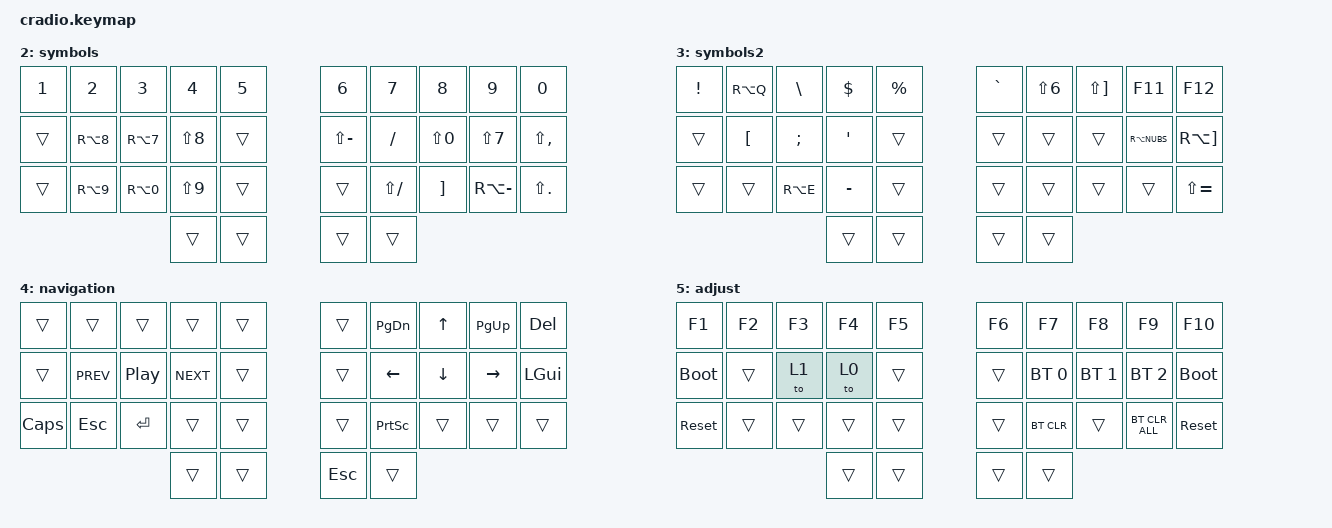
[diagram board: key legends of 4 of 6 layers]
#include <behaviors.dtsi>
#include <dt-bindings/zmk/keys.h>
#include <dt-bindings/zmk/bt.h>

// Home row mods macro
#define HRML(k1,k2,k3,k4) &hrm LGUI k1  &hrm LALT k2  &hrm LSHFT k3  &hrm LCTRL k4
#define HRMR(k1,k2,k3,k4) &hrm RCTRL k1  &hrm RSHFT k2  &hrm LALT k3  &hrm LGUI k4

&lt {
    flavor = "balanced";
    tapping-term-ms = <225>;
};

&sk {
    release-after-ms = <125>;
    quick-release;
};

/ {
    behaviors {
        hrm: home_row_mod {
            compatible = "zmk,behavior-hold-tap";
            #binding-cells = <2>;
            flavor = "balanced";
            tapping-term-ms = <225>;
            quick-tap-ms = <150>;
            require-prior-idle-ms = <150>;
            bindings = <&kp>, <&kp>;
        };

        m_com: morph_comma {
            compatible = "zmk,behavior-mod-morph";
            #binding-cells = <0>;
            bindings = <&kp COMMA>, <&kp NUBS>;
            mods = <(MOD_LSFT|MOD_RSFT)>;
        };
        m_dot: morph_dot {
            compatible = "zmk,behavior-mod-morph";
            #binding-cells = <0>;
            bindings = <&kp DOT>, <&kp NUBS>;
            mods = <(MOD_LSFT|MOD_RSFT)>;
            keep-mods = <(MOD_LSFT)>;
        };
        m_quot: morph_quotation {
            compatible = "zmk,behavior-mod-morph";
            #binding-cells = <0>;
            bindings = <&kp LS(BSLH)>, <&kp N2>;
            mods = <(MOD_LSFT|MOD_RSFT)>;
            keep-mods = <(MOD_LSFT)>;
        };
    };

    conditional_layers {
        compatible = "zmk,conditional-layers";
        adjust {
            if-layers = <3 4>;
            then-layer = <5>;
        };
    };

    keymap {
        compatible = "zmk,keymap";
        default_layer {
            bindings = <
        //╭──────────┬──────────┬──────────┬──────────┬──────────╮   ╭──────────┬──────────┬──────────┬──────────┬──────────╮
        //│  B       │  L       │  D       │  W       │  Z       │   │  J       │  F       │  O       │  U       │  BSPC    │
            &kp B      &kp L      &kp D      &kp W      &kp Y          &kp J      &kp F      &kp O      &kp U      &kp BSPC
        //├──────────┼──────────┼──────────┼──────────┼──────────┤   ├──────────┼──────────┼──────────┼──────────┼──────────┤
        //│  N       │  R       │  T       │  S       │  G       │   │  Y       │  H       │  A       │  E       │  I       │
            HRML(N,        R,         T,         S)     &kp G          &kp Z      HRMR(H,        A,         E,         I)
        //├──────────┼──────────┼──────────┼──────────┼──────────┤   ├──────────┼──────────┼──────────┼──────────┼──────────┤
        //│  Q       │  X       │  M       │  C       │  V       │   │  K       │  P       │ , <      │ . >      │ ' "      │
            &kp Q      &kp X      &kp M      &kp C      &kp V          &kp K      &kp P      &m_com     &m_dot     &m_quot
        //╰──────────┴──────────┴──────────┼──────────┼──────────┤   ├──────────┼──────────┼──────────┴──────────┴──────────╯
                                            &lt 4 TAB   &sk LSHFT    &lt 2 SPACE &lt 3 ENTER
        //                                 ╰──────────┴──────────╯   ╰──────────┴──────────╯
            >;  
        };

        default_layer_colemak {
            bindings = <
        //╭──────────┬──────────┬──────────┬──────────┬──────────╮   ╭──────────┬──────────┬──────────┬──────────┬──────────╮
        //│  Q       │  W       │  F       │  P       │  B       │   │  J       │  L       │  U       │  Y       │  BSPC    │
            &kp Q      &kp W      &kp F      &kp P      &kp B          &kp J      &kp L      &kp U      &kp Z      &kp BSPC
        //├──────────┼──────────┼──────────┼──────────┼──────────┤   ├──────────┼──────────┼──────────┼──────────┼──────────┤
        //│  A       │  R       │  S       │  T       │  G       │   │  M       │  N       │  E       │  I       │  O       │
            HRML(A,        R,         S,         T)     &kp G          &kp M      HRMR(N,        E,         I,         O)
        //├──────────┼──────────┼──────────┼──────────┼──────────┤   ├──────────┼──────────┼──────────┼──────────┼──────────┤
        //│  Z       │  X       │  C       │  D       │  V       │   │  K       │  H       │ , <      │ . >      │ ' "      │
            &kp Y      &kp X      &kp C      &kp D      &kp V          &kp K      &kp H      &m_com     &m_dot     &m_quot
        //╰──────────┴──────────┴──────────┼──────────┼──────────┤   ├──────────┼──────────┼──────────┴──────────┴──────────╯
                                            &lt 4 TAB   &sk LSHFT    &lt 2 SPACE &lt 3 ENTER
        //                                 ╰──────────┴──────────╯   ╰──────────┴──────────╯
            >;
        };

        symbols {
            bindings = <
        //╭──────────┬──────────┬──────────┬──────────┬──────────╮   ╭──────────┬──────────┬──────────┬──────────┬──────────╮
        //│  1       │  2       │  3       │  4       │  5       │   │  6       │  7       │  8       │  9       │  0       │
            &kp N1     &kp N2     &kp N3     &kp N4     &kp N5         &kp N6     &kp N7     &kp N8     &kp N9     &kp N0
        //├──────────┼──────────┼──────────┼──────────┼──────────┤   ├──────────┼──────────┼──────────┼──────────┼──────────┤
        //│          │  [       │  {       │  (       │          │   │  ?       │  -       │  =       │  /       │  ;       │
            &trans    &kp RA(N8) &kp RA(N7) &kp LS(N8)  &trans      &kp LS(MINUS) &kp SLASH &kp LS(N0) &kp LS(N7) &kp LS(COMMA)
        //├──────────┼──────────┼──────────┼──────────┼──────────┤   ├──────────┼──────────┼──────────┼──────────┼──────────┤
        //│          │  ]       │  }       │  )       │          │   │          │  _       │  +       │  \       │  :       │
            &trans    &kp RA(N9) &kp RA(N0) &kp LS(N9)  &trans         &trans  &kp LS(SLASH) &kp RBKT &kp RA(MINUS) &kp LS(DOT)
        //╰──────────┴──────────┴──────────┼──────────┼──────────┤   ├──────────┼──────────┼──────────┴──────────┴──────────╯
                                             &trans     &trans         &trans     &trans
        //                                 ╰──────────┴──────────╯   ╰──────────┴──────────╯
            >;
        };

        symbols2 {
            bindings = <
        //╭──────────┬──────────┬──────────┬──────────┬──────────╮   ╭──────────┬──────────┬──────────┬──────────┬──────────╮
        //│  !       │  @       │  #       │  $       │  %       │   │  ^       │  &       │  *       │  F11     │  F12     │
           &kp EXCL   &kp RA(Q)  &kp BSLH   &kp DLLR   &kp PRCNT      &kp GRAVE  &kp LS(N6) &kp LS(RBKT) &kp F11   &kp F12
        //├──────────┼──────────┼──────────┼──────────┼──────────┤   ├──────────┼──────────┼──────────┼──────────┼──────────┤
        //│          │  ü       │  ö       │  ä       │          │   │          │          │          │   |      │  ~       │
            &trans     &kp LBKT   &kp SEMI   &kp SQT    &trans          &trans     &trans     &trans &kp RA(NUBS) &kp RA(RBKT)
        //├──────────┼──────────┼──────────┼──────────┼──────────┤   ├──────────┼──────────┼──────────┼──────────┼──────────┤
        //│          │          │  €       │  ß       │          │   │          │          │          │          │  `       │
            &trans     &trans    &kp RA(E)  &kp MINUS    &trans         &trans     &trans     &trans     &trans  &kp LS(EQUAL)
        //╰──────────┴──────────┴──────────┼──────────┼──────────┤   ├──────────┼──────────┼──────────┴──────────┴──────────╯
                                             &trans     &trans         &trans     &trans
        //                                 ╰──────────┴──────────╯   ╰──────────┴──────────╯
            >;
        };

        navigation {
            bindings = <
        //╭──────────┬──────────┬──────────┬──────────┬──────────╮   ╭──────────┬──────────┬──────────┬──────────┬──────────╮
        //│          │          │          │          │          │   │          │ PageDown │   Up     │ PageUp   │ Delete   │
             &trans     &trans     &trans     &trans     &trans         &trans   &kp PG_DN   &kp UP    &kp PG_UP   &kp DEL
        //├──────────┼──────────┼──────────┼──────────┼──────────┤   ├──────────┼──────────┼──────────┼──────────┼──────────┤
        //│          │ Previous │Play/Pause│  Next    │          │   │          │  Left    │  Down    │  Right   │  GUI     │
             &trans   &kp C_PREV  &kp C_PP  &kp C_NEXT   &trans         &trans    &kp LEFT   &kp DOWN  &kp RIGHT  &kp LGUI
        //├──────────┼──────────┼──────────┼──────────┼──────────┤   ├──────────┼──────────┼──────────┼──────────┼──────────┤
        //│          │          │          │          │          │   │          │ PrintScr │          │          │          │
            &kp CAPS   &kp ESC   &kp ENTER    &trans     &trans         &trans   &kp PSCRN    &trans     &trans     &trans
        //╰──────────┴──────────┴──────────┼──────────┼──────────┤   ├──────────┼──────────┼──────────┴──────────┴──────────╯
                                             &trans     &trans         &kp ESC     &trans
        //                                 ╰──────────┴──────────╯   ╰──────────┴──────────╯
            >;
        };

        adjust {
            bindings = <
        //╭──────────┬──────────┬──────────┬──────────┬──────────╮   ╭──────────┬──────────┬──────────┬──────────┬──────────╮
        //│  F1      │  F2      │  F3      │  F4      │  F5      │   │  F6      │  F7      │  F8      │  F9      │  F10     │
            &kp F1     &kp F2     &kp F3     &kp F4     &kp F5         &kp F6     &kp F7     &kp F8     &kp F9     &kp F10
        //├──────────┼──────────┼──────────┼──────────┼──────────┤   ├──────────┼──────────┼──────────┼──────────┼──────────┤
        //│BOOTLOADER│          │ Colemak  │ Graphite │          │   │          │PROFILE 0 │PROFILE 1 │PROFILE 2 │BOOTLOADER│
          &bootloader   &trans     &to 1     &to 0     &trans        &trans &bt BT_SEL 0 &bt BT_SEL 1 &bt BT_SEL 2 &bootloader
        //├──────────┼──────────┼──────────┼──────────┼──────────┤   ├──────────┼──────────┼──────────┼──────────┼──────────┤
        //│ RESET    │          │          │          │          │   │          │  CLEAR   │          │CLEAR ALL │  RESET   │
           &sys_reset   &trans     &trans     &trans     &trans         &trans   &bt BT_CLR   &trans &bt BT_CLR_ALL &sys_reset
        //╰──────────┴──────────┴──────────┼──────────┼──────────┤   ├──────────┼──────────┼──────────┴──────────┴──────────╯
                                              &trans     &trans         &trans     &trans
        //                                 ╰──────────┴──────────╯   ╰──────────┴──────────╯
            >;
        };
    };
};
